# STM32G0C1VET6 register map
File version: 1.0
Registers are 32-bit, access not given, reset 0x0 unless marked. A register's access mark holds for its fields unless they carry their own. Offsets are from the block's base; [hi:lo] are bit positions; {n}, {i} and the like mark numbered series.

## DMAMUX1
Base 0x40020800
0x00 CCR0
0x04 CCR1
0x08 CCR2
0x0C CCR3
{0x0+4i} CCR{i} (i=4..9)
0x28 CCR0
0x2C CCR1
0x80 CCRs
0x100 CCR0
0x104 CCR1
0x108 CCR2
0x10C CCR3
0x140 CCRs

## EXTI
Base 0x40021800
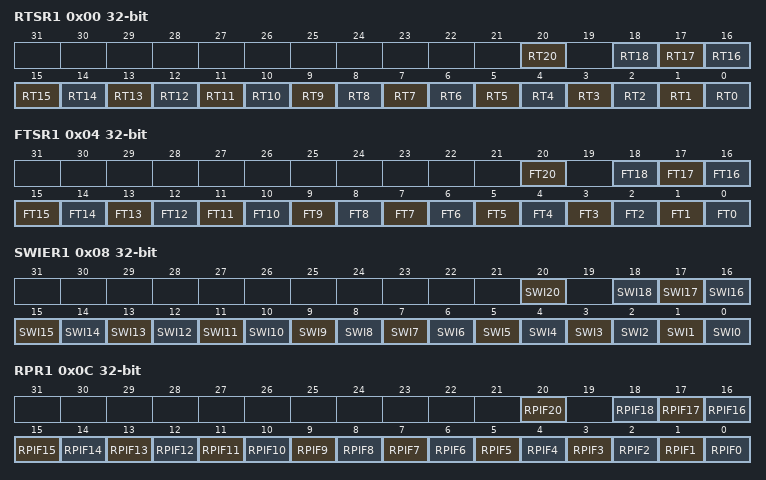
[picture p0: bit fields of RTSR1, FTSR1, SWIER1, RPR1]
0x00 RTSR1
  [20] RT20, [n] RT{n} (n=0..18)
0x04 FTSR1
  [20] FT20, [n] FT{n} (n=0..18)
0x08 SWIER1
  [20] SWI20, [n] SWI{n} (n=0..18)
0x0C RPR1
  [20] RPIF20, [n] RPIF{n} (n=0..18)
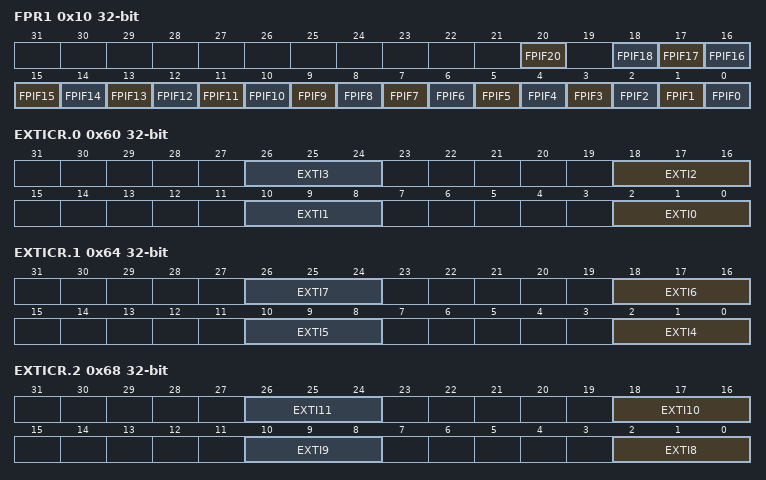
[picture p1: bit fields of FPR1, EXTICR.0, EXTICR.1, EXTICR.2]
0x10 FPR1
  [20] FPIF20, [n] FPIF{n} (n=0..18)
0x20 RTSR2
  [2] RT34
0x24 FTSR2
  [2] FT34
0x28 SWIER2
  [2] SWI34
0x2C RPR2
  [2] RPIF34
0x30 FPR2
  [2] RPIF34
0x60 EXTICR.0
  [8n+2:8n] EXTI{n} (n=0..3)
0x64 EXTICR.1
  [8n-30:8n-32] EXTI{n} (n=4..7)
0x68 EXTICR.2
  [8n-62:8n-64] EXTI{n} (n=8..11)
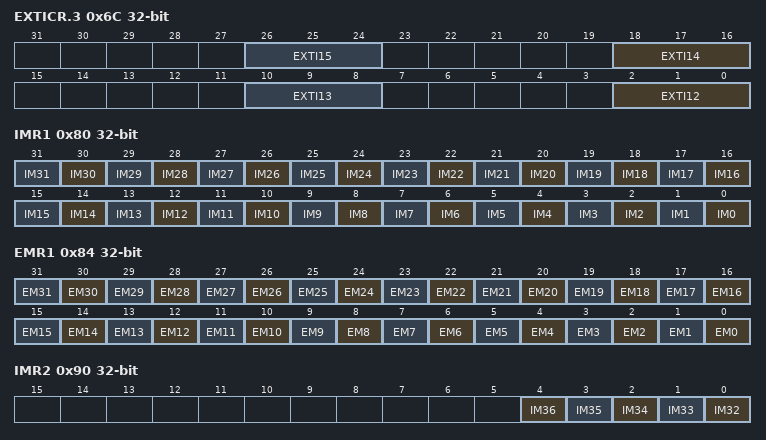
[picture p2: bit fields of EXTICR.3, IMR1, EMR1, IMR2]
0x6C EXTICR.3
  [8n-94:8n-96] EXTI{n} (n=12..15)
0x80 IMR1
  [n] IM{n} (n=0..31)
0x84 EMR1
  [n] EM{n} (n=0..31)
0x90 IMR2
  [n-32] IM{n} (n=32..36)
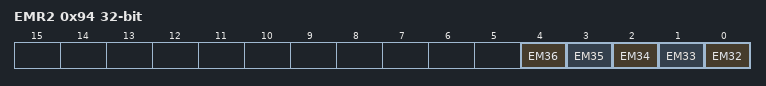
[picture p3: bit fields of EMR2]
0x94 EMR2
  [n-32] EM{n} (n=32..36)

## FLASH
Base 0x40022000
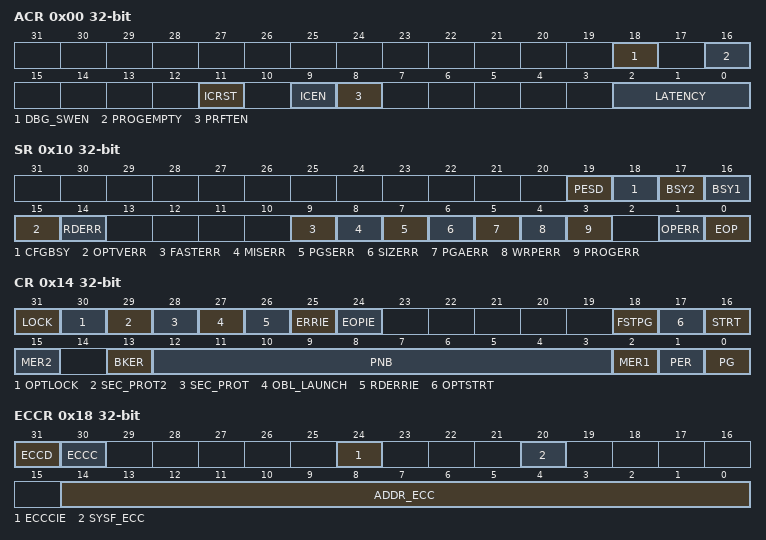
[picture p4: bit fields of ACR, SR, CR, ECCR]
0x00 ACR
  [18] DBG_SWEN, [16] PROGEMPTY, [11] ICRST, [9] ICEN, [8] PRFTEN, [2:0] LATENCY
0x08 KEYR
0x0C OPTKEYR
0x10 SR
  [19] PESD, [18] CFGBSY, [17] BSY2, [16] BSY1, [15] OPTVERR, [14] RDERR, [9] FASTERR, [8] MISERR, [7] PGSERR, [6] SIZERR, [5] PGAERR, [4] WRPERR, [3] PROGERR, [1] OPERR, [0] EOP
0x14 CR
  [31] LOCK, [30] OPTLOCK, [29] SEC_PROT2, [28] SEC_PROT, [27] OBL_LAUNCH, [26] RDERRIE, [25] ERRIE, [24] EOPIE, [18] FSTPG, [17] OPTSTRT, [16] STRT, [15] MER2, [13] BKER, [12:3] PNB, [2] MER1, [1] PER, [0] PG
0x18 ECCR
  [31] ECCD, [30] ECCC, [24] ECCCIE, [20] SYSF_ECC, [14:0] ADDR_ECC
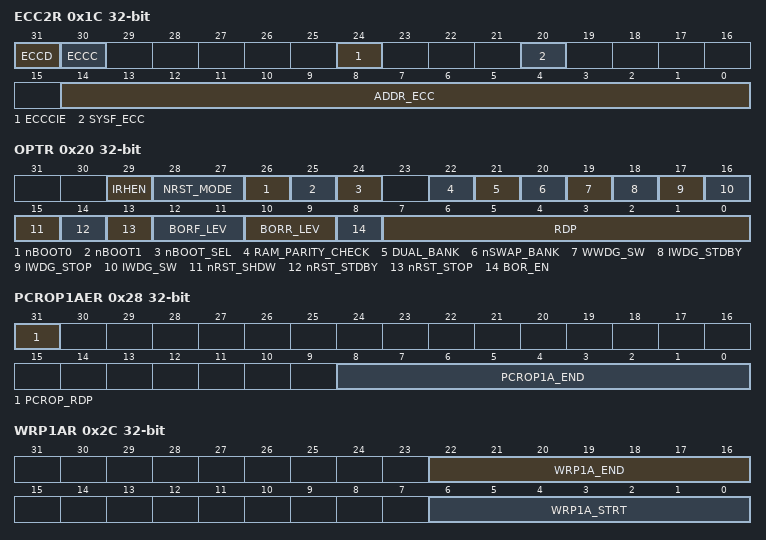
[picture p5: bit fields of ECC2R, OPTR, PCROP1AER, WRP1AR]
0x1C ECC2R
  [31] ECCD, [30] ECCC, [24] ECCCIE, [20] SYSF_ECC, [14:0] ADDR_ECC
0x20 OPTR
  [29] IRHEN, [28:27] NRST_MODE, [26] nBOOT0, [25] nBOOT1, [24] nBOOT_SEL, [22] RAM_PARITY_CHECK, [21] DUAL_BANK, [20] nSWAP_BANK, [19] WWDG_SW, [18] IWDG_STDBY, [17] IWDG_STOP, [16] IWDG_SW, [15] nRST_SHDW, [14] nRST_STDBY, [13] nRST_STOP, [12:11] BORF_LEV, [10:9] BORR_LEV, [8] BOR_EN, [7:0] RDP
0x24 PCROP1ASR
  [8:0] PCROP1A_STRT
0x28 PCROP1AER
  [31] PCROP_RDP, [8:0] PCROP1A_END
0x2C WRP1AR
  [22:16] WRP1A_END, [6:0] WRP1A_STRT
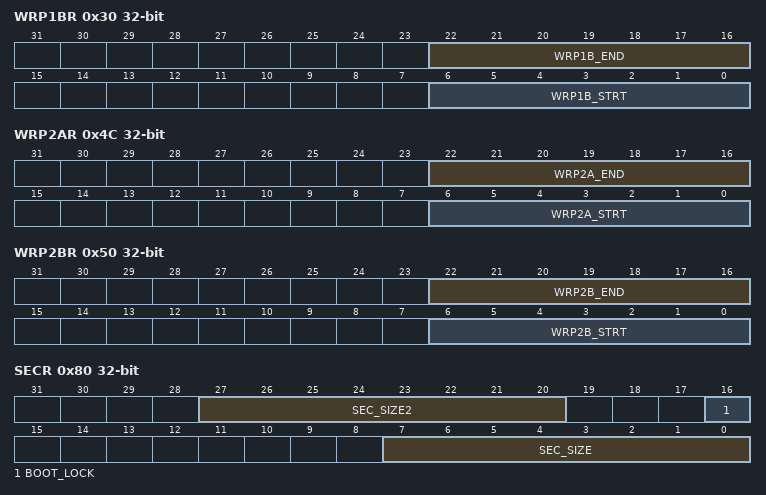
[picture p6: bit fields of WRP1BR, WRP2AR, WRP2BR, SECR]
0x30 WRP1BR
  [22:16] WRP1B_END, [6:0] WRP1B_STRT
0x34 PCROP1BSR
  [8:0] PCROP1B_STRT
0x38 PCROP1BER
  [8:0] PCROP1B_END
0x44 PCROP2ASR
  [8:0] PCROP2A_STRT
0x48 PCROP2AER
  [8:0] PCROP2A_END
0x4C WRP2AR
  [22:16] WRP2A_END, [6:0] WRP2A_STRT
0x50 WRP2BR
  [22:16] WRP2B_END, [6:0] WRP2B_STRT
0x54 PCROP2BSR
  [8:0] PCROP2B_STRT
0x58 PCROP2BER
  [8:0] PCROP2B_END
0x80 SECR
  [27:20] SEC_SIZE2, [16] BOOT_LOCK, [7:0] SEC_SIZE

## CRC
Base 0x40023000
0x00 DR
0x04 IDR
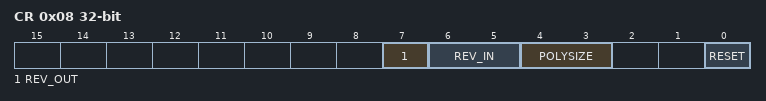
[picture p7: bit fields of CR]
0x08 CR
  [7] REV_OUT, [6:5] REV_IN, [4:3] POLYSIZE, [0] RESET
0x10 INIT
0x14 POL

## RNG
Base 0x40025000
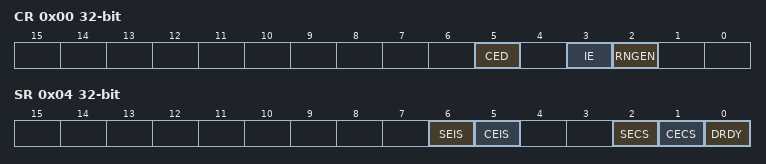
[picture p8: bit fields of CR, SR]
0x00 CR
  [5] CED, [3] IE, [2] RNGEN
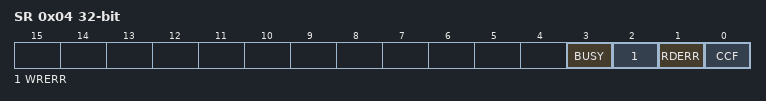
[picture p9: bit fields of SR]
0x04 SR
  [6] SEIS, [5] CEIS, [2] SECS, [1] CECS, [0] DRDY
0x08 DR

## AES
Base 0x40026000
Same registers: AES1 0x40026000
0x00 CR
  [23:20] NPBLB, [18] KEYSIZE, [14:13] GCMPH, [12] DMAOUTEN, [11] DMAINEN, [10] ERRIE, [9] CCFIE, [8] ERRC, [7] CCFC, [16:5] CHMOD, [4:3] MODE, [2:1] DATATYPE, [0] EN
0x04 SR
  [3] BUSY, [2] WRERR, [1] RDERR, [0] CCF
0x08 DINR
0x0C DOUTR
{0x10+4i} KEYR{i} (i=0..3)
{0x20+4i} IVR{i} (i=0..3)
{0x20+4i} KEYR{i} (i=4..7)
{0x40+4i} SUSP{i}R (i=0..7)

## GPIOA
Base 0x50000000
Same registers: GPIOB 0x50000400, GPIOC 0x50000800, GPIOD 0x50000C00, GPIOE 0x50001000, GPIOF 0x50001400
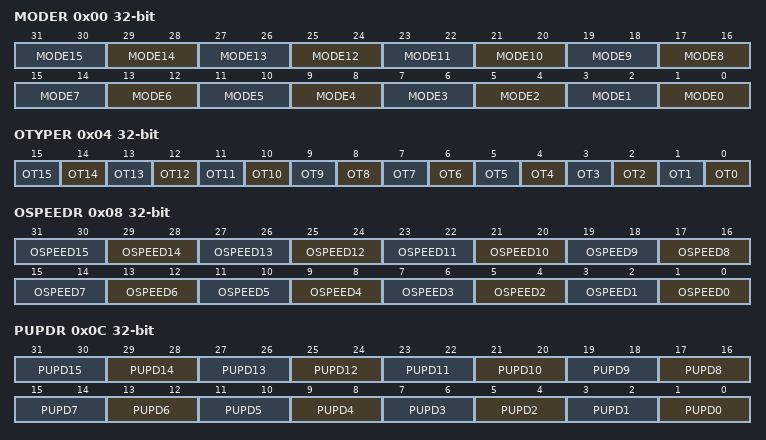
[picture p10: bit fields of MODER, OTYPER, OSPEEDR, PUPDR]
0x00 MODER
  [2n+1:2n] MODE{n} (n=0..15)
0x04 OTYPER
  [n] OT{n} (n=0..15)
0x08 OSPEEDR
  [2n+1:2n] OSPEED{n} (n=0..15)
0x0C PUPDR
  [2n+1:2n] PUPD{n} (n=0..15)
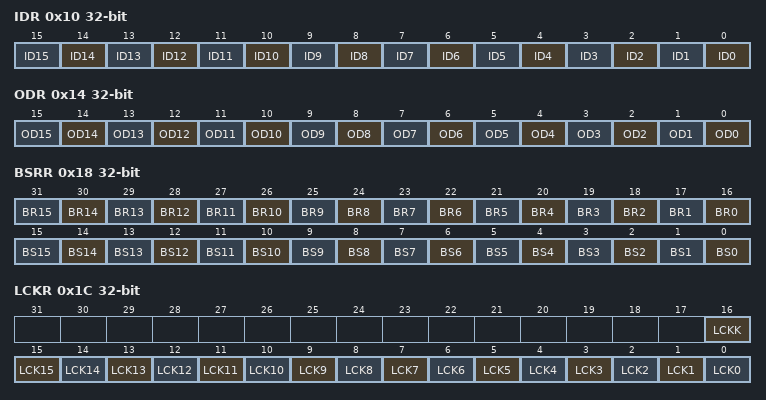
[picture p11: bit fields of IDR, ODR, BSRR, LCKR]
0x10 IDR
  [n] ID{n} (n=0..15)
0x14 ODR
  [n] OD{n} (n=0..15)
0x18 BSRR
  [n+16] BR{n} (n=0..15), [n] BS{n} (n=0..15)
0x1C LCKR
  [16] LCKK, [n] LCK{n} (n=0..15)
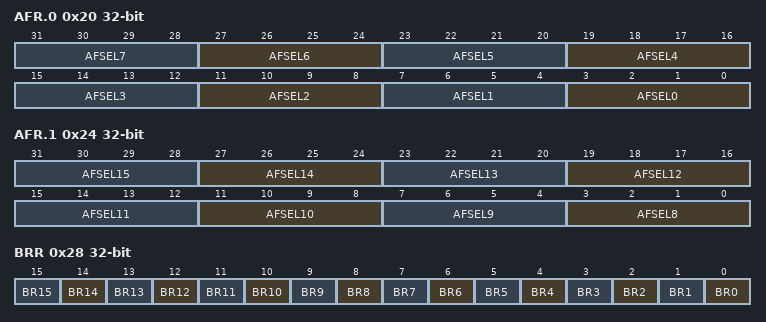
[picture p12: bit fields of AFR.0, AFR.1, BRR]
0x20 AFR.0
  [4n+3:4n] AFSEL{n} (n=0..7)
0x24 AFR.1
  [4n-29:4n-32] AFSEL{n} (n=8..15)
0x28 BRR
  [n] BR{n} (n=0..15)
